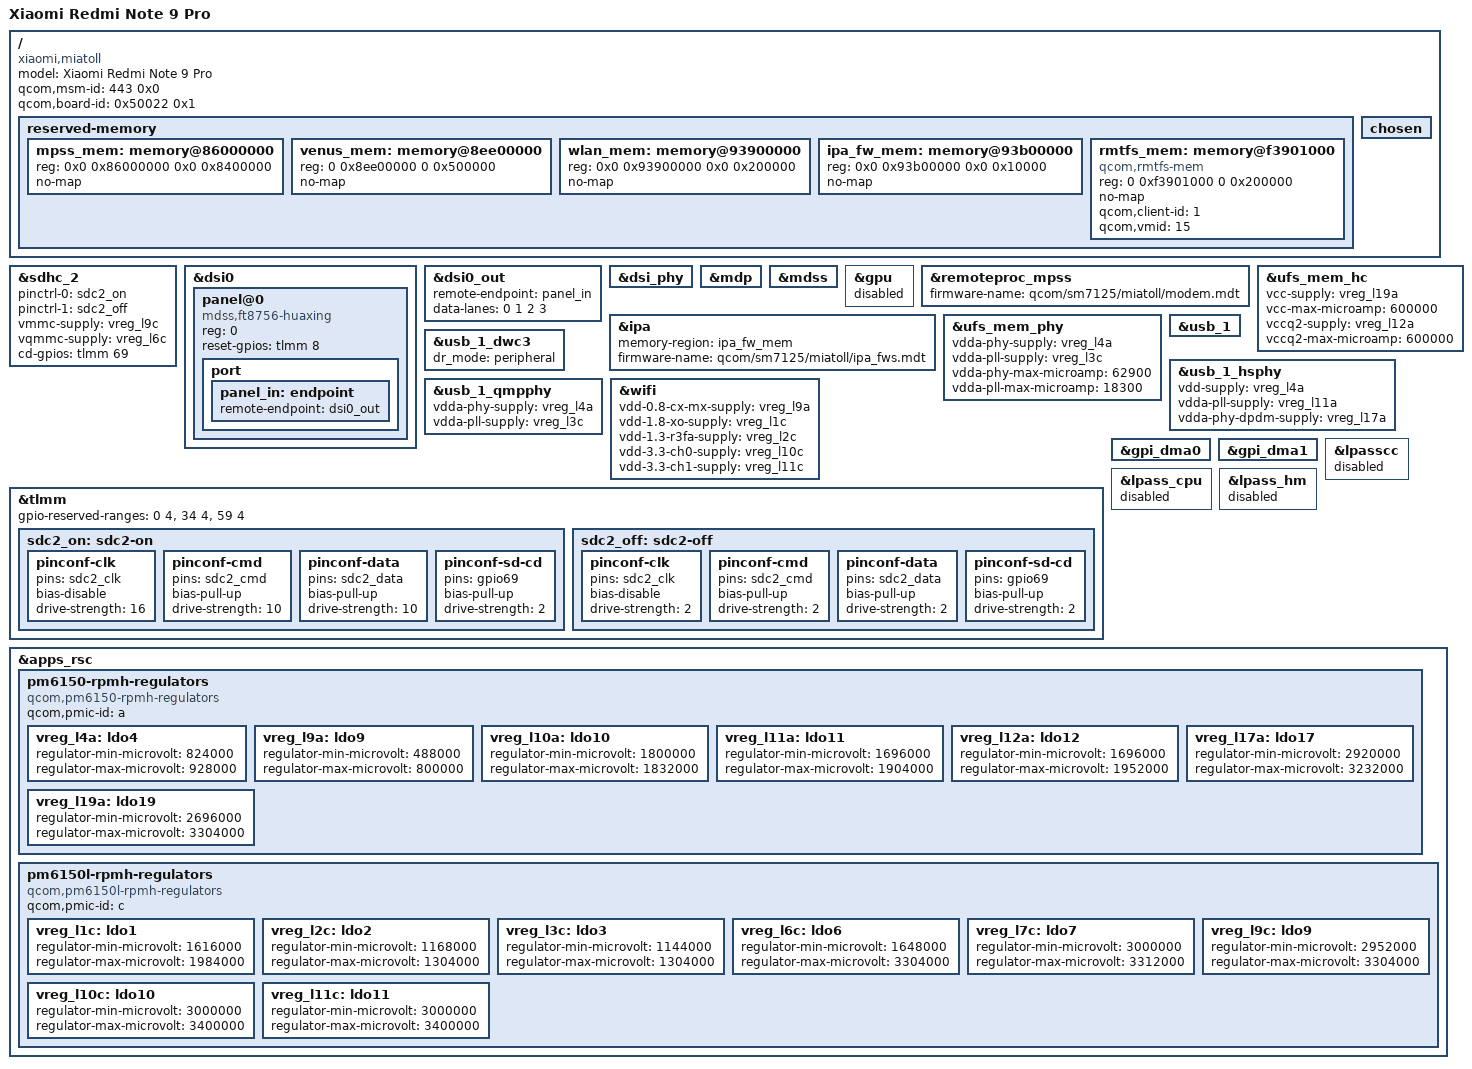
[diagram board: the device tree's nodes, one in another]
/dts-v1/;

#include <dt-bindings/gpio/gpio.h>
#include <dt-bindings/regulator/qcom,rpmh-regulator.h>
#include <dt-bindings/pinctrl/qcom,pmic-gpio.h>
#include "sm7125.dtsi"
#include "pm6150.dtsi"
#include "pm6150l.dtsi"

/delete-node/ &rmtfs_mem;
/delete-node/ &ipa_fw_mem;

/ {
	model = "Xiaomi Redmi Note 9 Pro";
	compatible = "xiaomi,miatoll", "qcom,sm7125";
	qcom,msm-id = <443 0x0>;
	qcom,board-id = <0x50022 0x1>;

        reserved-memory {
		#address-cells = <2>;
		#size-cells = <2>;
		ranges;

		mpss_mem: memory@86000000 {
			reg = <0x0 0x86000000 0x0 0x8400000>;
			no-map;
		};

		venus_mem: memory@8ee00000 {
			reg = <0 0x8ee00000 0 0x500000>;
			no-map;
		};

		wlan_mem: memory@93900000 {
			reg = <0x0 0x93900000 0x0 0x200000>;
			no-map;
		};

		ipa_fw_mem: memory@93b00000 {
			reg = <0x0 0x93b00000 0x0 0x10000>;
			no-map;
		};

		rmtfs_mem: memory@f3901000 {
			compatible = "qcom,rmtfs-mem";
			reg = <0 0xf3901000 0 0x200000>;
			no-map;

			qcom,client-id = <1>;
			qcom,vmid = <15>;
		};
        };

	chosen {
		#address-cells = <2>;
		#size-cells = <2>;
		ranges;
	};
};

&sdhc_2 {
	status = "okay";

	pinctrl-names = "default", "sleep";
	pinctrl-0 = <&sdc2_on>;
	pinctrl-1 = <&sdc2_off>;
	vmmc-supply = <&vreg_l9c>;
	vqmmc-supply = <&vreg_l6c>;

	cd-gpios = <&tlmm 69 GPIO_ACTIVE_HIGH>;
};

&dsi0 {
	status = "okay";

	panel@0 {
		status = "okay";
		compatible = "mdss,ft8756-huaxing";
		reg = <0>;

		reset-gpios = <&tlmm 8 GPIO_ACTIVE_HIGH>;

		port {
			panel_in: endpoint {
				remote-endpoint = <&dsi0_out>;
			};
		};
	};
};

&dsi0_out {
	remote-endpoint = <&panel_in>;
	data-lanes = <0 1 2 3>;
};

&dsi_phy {
	status = "okay";
};

&mdp {
	status = "okay";
};

&mdss {
	status = "okay";
};

&gpu {
	status = "disabled";
};

&remoteproc_mpss {
	status = "okay";
	firmware-name = "qcom/sm7125/miatoll/modem.mdt";
};

&ipa {
	status = "okay";

	memory-region = <&ipa_fw_mem>;
	firmware-name = "qcom/sm7125/miatoll/ipa_fws.mdt";
};

&ufs_mem_hc {
	status = "okay";

	vcc-supply = <&vreg_l19a>;
	vcc-max-microamp = <600000>;
	vccq2-supply = <&vreg_l12a>;
	vccq2-max-microamp = <600000>;
};

&ufs_mem_phy {
	status = "okay";

	vdda-phy-supply = <&vreg_l4a>;
	vdda-pll-supply = <&vreg_l3c>;
	vdda-phy-max-microamp = <62900>;
	vdda-pll-max-microamp = <18300>;
};

&usb_1 {
	status = "okay";
};

&usb_1_dwc3 {
	dr_mode = "peripheral";
};

&usb_1_hsphy {
	status = "okay";
	vdd-supply = <&vreg_l4a>;
	vdda-pll-supply = <&vreg_l11a>;
	vdda-phy-dpdm-supply = <&vreg_l17a>;
};

&usb_1_qmpphy {
	status = "okay";
	vdda-phy-supply = <&vreg_l4a>;
	vdda-pll-supply = <&vreg_l3c>;
};

&wifi {
	status = "okay";

	vdd-0.8-cx-mx-supply = <&vreg_l9a>;
	vdd-1.8-xo-supply = <&vreg_l1c>;
	vdd-1.3-r3fa-supply = <&vreg_l2c>;
	vdd-3.3-ch0-supply = <&vreg_l10c>;
	vdd-3.3-ch1-supply = <&vreg_l11c>;
};

&tlmm {
	gpio-reserved-ranges = <0 4>, <34 4>, <59 4>;

	sdc2_on: sdc2-on {
		pinconf-clk {
			pins = "sdc2_clk";
			bias-disable;
			drive-strength = <16>;
		};

		pinconf-cmd {
			pins = "sdc2_cmd";
			bias-pull-up;
			drive-strength = <10>;
		};

		pinconf-data {
			pins = "sdc2_data";
			bias-pull-up;
			drive-strength = <10>;
		};

		pinconf-sd-cd {
			pins = "gpio69";
			bias-pull-up;
			drive-strength = <2>;
		};
	};

	sdc2_off: sdc2-off {
		pinconf-clk {
			pins = "sdc2_clk";
			bias-disable;
			drive-strength = <2>;
		};

		pinconf-cmd {
			pins = "sdc2_cmd";
			bias-pull-up;
			drive-strength = <2>;
		};

		pinconf-data {
			pins = "sdc2_data";
			bias-pull-up;
			drive-strength = <2>;
		};

		pinconf-sd-cd {
			pins = "gpio69";
			bias-pull-up;
			drive-strength = <2>;
		};
	};
};

&gpi_dma0 {
	status = "okay";
};

&gpi_dma1 {
	status = "okay";
};

&lpasscc {
	status = "disabled";
};

&lpass_cpu {
	status = "disabled";
};

&lpass_hm {
	status = "disabled";
};

&apps_rsc {
	pm6150-rpmh-regulators {
		compatible = "qcom,pm6150-rpmh-regulators";
		qcom,pmic-id = "a";

		vreg_l4a: ldo4 {
			regulator-min-microvolt = <824000>;
			regulator-max-microvolt = <928000>;
		};

		vreg_l9a: ldo9 {
			regulator-min-microvolt = <488000>;
			regulator-max-microvolt = <800000>;
		};

		vreg_l10a: ldo10 {
			regulator-min-microvolt = <1800000>;
			regulator-max-microvolt = <1832000>;
		};

		vreg_l11a: ldo11 {
			regulator-min-microvolt = <1696000>;
			regulator-max-microvolt = <1904000>;
		};

		vreg_l12a: ldo12 {
			regulator-min-microvolt = <1696000>;
			regulator-max-microvolt = <1952000>;
		};

		vreg_l17a: ldo17 {
			regulator-min-microvolt = <2920000>;
			regulator-max-microvolt = <3232000>;
		};

		vreg_l19a: ldo19 {
			regulator-min-microvolt = <2696000>;
			regulator-max-microvolt = <3304000>;
		};
	};

	pm6150l-rpmh-regulators {
		compatible = "qcom,pm6150l-rpmh-regulators";
		qcom,pmic-id = "c";

		vreg_l1c: ldo1 {
			regulator-min-microvolt = <1616000>;
			regulator-max-microvolt = <1984000>;
		};

		vreg_l2c: ldo2 {
			regulator-min-microvolt = <1168000>;
			regulator-max-microvolt = <1304000>;
		};

		vreg_l3c: ldo3 {
			regulator-min-microvolt = <1144000>;
			regulator-max-microvolt = <1304000>;
		};

		vreg_l6c: ldo6 {
			regulator-min-microvolt = <1648000>;
			regulator-max-microvolt = <3304000>;
		};

		vreg_l7c: ldo7 {
			regulator-min-microvolt = <3000000>;
			regulator-max-microvolt = <3312000>;
		};

		vreg_l9c: ldo9 {
			regulator-min-microvolt = <2952000>;
			regulator-max-microvolt = <3304000>;
		};

		vreg_l10c: ldo10 {
			regulator-min-microvolt = <3000000>;
			regulator-max-microvolt = <3400000>;
		};

		vreg_l11c: ldo11 {
			regulator-min-microvolt = <3000000>;
			regulator-max-microvolt = <3400000>;
		};
	};
};
